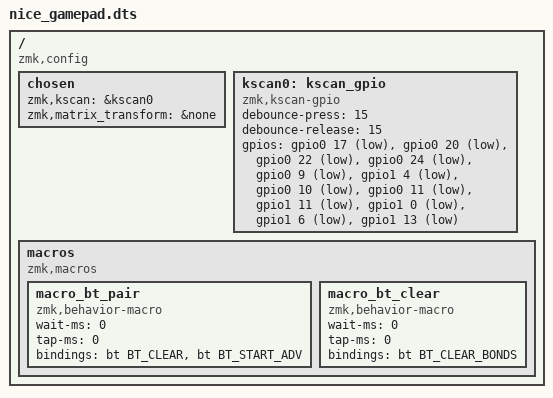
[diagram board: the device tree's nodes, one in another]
#include <dt-bindings/gpio/gpio.h>
#include <dt-bindings/zmk/keys.h>

/ {
    compatible = "zmk,config";

    chosen {
        zmk,kscan = &kscan0;
        zmk,matrix_transform = &none;
    };

    kscan0: kscan_gpio {
        compatible = "zmk,kscan-gpio";
        debounce-press = <15>;   /*导电胶按下消抖15ms*/
        debounce-release = <15>; /*松开消抖15ms*/

        gpios =
            <&gpio0 17 GPIO_ACTIVE_LOW>,  /* P0.17 W */
            <&gpio0 20 GPIO_ACTIVE_LOW>,  /* P0.20 A */
            <&gpio0 22 GPIO_ACTIVE_LOW>,  /* P0.22 S */
            <&gpio0 24 GPIO_ACTIVE_LOW>,  /* P0.24 D */
            <&gpio0 9  GPIO_ACTIVE_LOW>,  /* P0.09 SPACE */
            <&gpio1 4  GPIO_ACTIVE_LOW>,  /* P1.04 F */
            <&gpio0 10 GPIO_ACTIVE_LOW>,  /* P0.10 E */
            <&gpio0 11 GPIO_ACTIVE_LOW>,  /* P0.11 UP */
            <&gpio1 11 GPIO_ACTIVE_LOW>,  /* P1.11 DOWN */
            <&gpio1 0  GPIO_ACTIVE_LOW>,  /* P1.00 R */
            <&gpio1 6  GPIO_ACTIVE_LOW>,  /* P1.06 LALT */
            <&gpio1 13 GPIO_ACTIVE_LOW>;  /* P1.13 TAB */
    };

    macros {
        compatible = "zmk,macros";
        /* Tab + W + S 触发蓝牙广播配对 */
        macro_bt_pair: macro_bt_pair {
            compatible = "zmk,behavior-macro";
            #binding-cells = <0>;
            wait-ms = <0>;
            tap-ms = <0>;
            bindings = <&bt BT_CLEAR &bt BT_START_ADV>;
        };
        /* Tab + A + D 清除全部蓝牙配对 */
        macro_bt_clear: macro_bt_clear {
            compatible = "zmk,behavior-macro";
            #binding-cells = <0>;
            wait-ms = <0>;
            tap-ms = <0>;
            bindings = <&bt BT_CLEAR_BONDS>;
        };
    };
};
